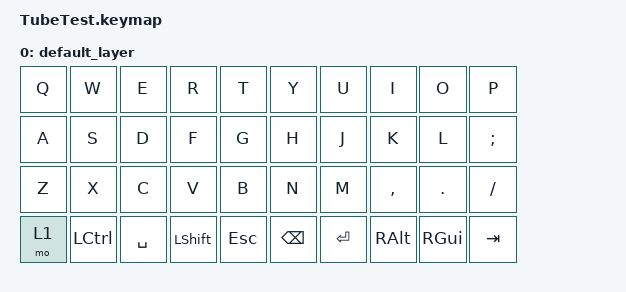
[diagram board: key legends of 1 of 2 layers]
#include <behaviors.dtsi>
#include <dt-bindings/zmk/keys.h>
#include <dt-bindings/zmk/bt.h>

 / {
    keymap {
        compatible = "zmk,keymap";

        default_layer {
            bindings = <
                &kp Q   &kp W   &kp E   &kp R   &kp T   &kp Y   &kp U   &kp I   &kp O   &kp P
                &kp A   &kp S   &kp D   &kp F   &kp G   &kp H   &kp J   &kp K   &kp L   &kp SEMI
                &kp Z   &kp X   &kp C   &kp V   &kp B   &kp N   &kp M   &kp COMMA  &kp DOT   &kp SLASH
                &mo 1   &kp LCTRL  &kp SPACE  &kp LSHIFT  &kp ESC  &kp BACKSPACE  &kp ENTER  &kp RALT  &kp RGUI  &kp TAB
            >;
        };
        
        layer_1 {
            bindings = <
                &kp N1   &kp N2   &kp N3   &kp N4   &kp N5   &kp N6   &kp N7   &kp N8   &kp N9   &kp N0
                &kp LEFT &kp DOWN &kp UP   &kp RIGHT &kp MINUS &kp EQUAL &kp LBRACKET &kp RBRACKET &kp BSLASH
                &kp TILDE &kp GRAVE &kp UNDERSCORE &kp PLUS &kp LCBR &kp RCBR &kp PIPE &kp SLASH &kp QUESTION &kp EXCLAIM
                &trans &trans &trans &trans &kp HOME &kp END &kp PGUP &kp PGDN &kp DEL &kp INS
            >;
        };
    };
};
